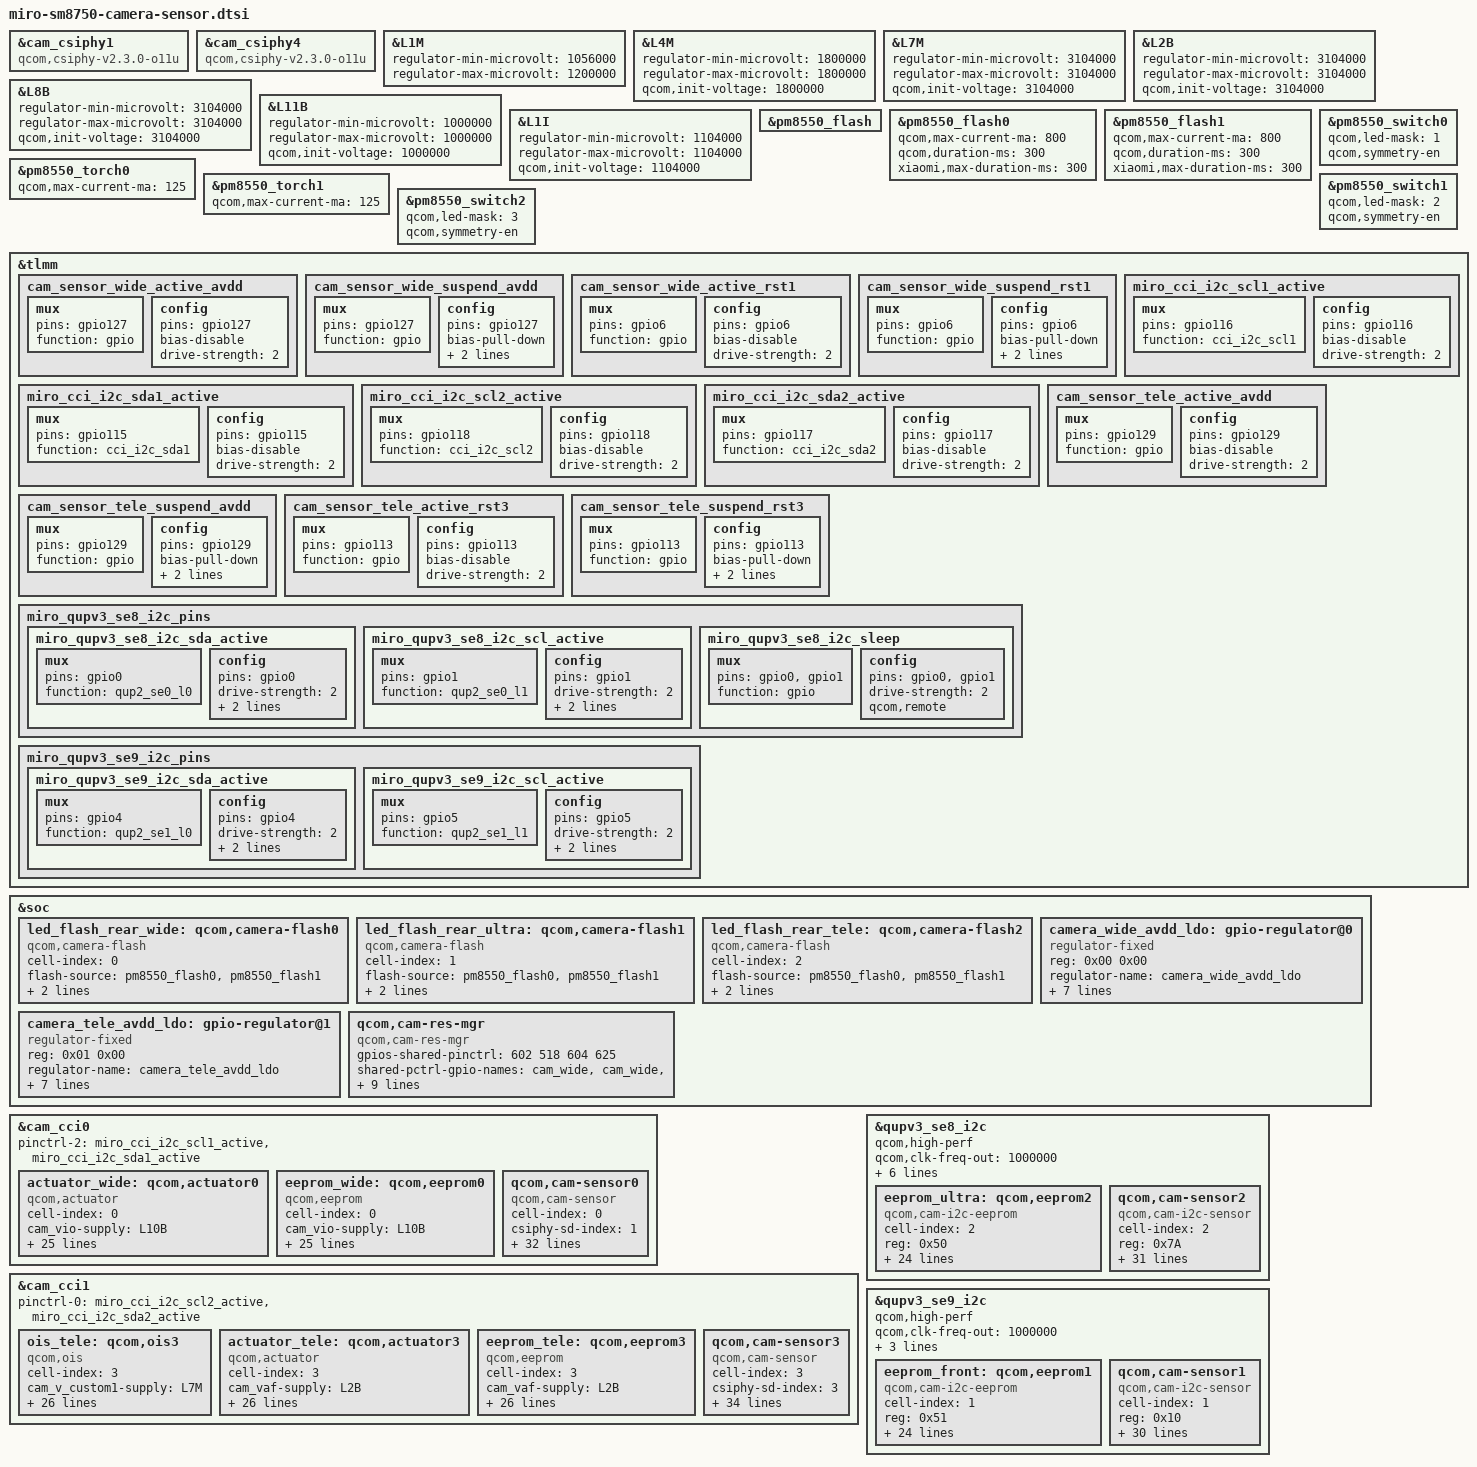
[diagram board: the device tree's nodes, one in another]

#include <dt-bindings/msm-camera.h>

// wide sensor
&cam_csiphy1 {
	compatible = "qcom,csiphy-v2.3.0-o11u", "qcom,csiphy";
};

// front sensor
&cam_csiphy4 {
	compatible = "qcom,csiphy-v2.3.0-o11u", "qcom,csiphy";
};

&L1M {
	regulator-min-microvolt = <1056000>;
	regulator-max-microvolt = <1200000>;
};

&L4M {
	regulator-min-microvolt = <1800000>;
	regulator-max-microvolt = <1800000>;
	qcom,init-voltage = <1800000>;
};

&L7M {
	regulator-min-microvolt = <3104000>;
	regulator-max-microvolt = <3104000>;
	qcom,init-voltage = <3104000>;
};

&L2B {
	regulator-min-microvolt = <3104000>;
	regulator-max-microvolt = <3104000>;
	qcom,init-voltage = <3104000>;
};

&L8B {
	regulator-min-microvolt = <3104000>;
	regulator-max-microvolt = <3104000>;
	qcom,init-voltage = <3104000>;
};

&L11B {
	regulator-min-microvolt = <1000000>;
	regulator-max-microvolt = <1000000>;
	qcom,init-voltage = <1000000>;
};

&L1I {
	regulator-min-microvolt = <1104000>;
	regulator-max-microvolt = <1104000>;
	qcom,init-voltage = <1104000>;
};

&pm8550_flash {
	status = "ok";
};

&pm8550_flash0 {
	qcom,max-current-ma = <800>;
	qcom,duration-ms = <300>;
	xiaomi,max-duration-ms = <300>;
};

&pm8550_flash1 {
	qcom,max-current-ma = <800>;
	qcom,duration-ms = <300>;
	xiaomi,max-duration-ms = <300>;
};

&pm8550_torch0{
	qcom,max-current-ma = <125>;
};

&pm8550_torch1{
	qcom,max-current-ma = <125>;
};

&pm8550_switch0 {
	qcom,led-mask = <1>;
	qcom,symmetry-en;
};

&pm8550_switch1 {
	qcom,led-mask = <2>;
	qcom,symmetry-en;
};

&pm8550_switch2 {
	qcom,led-mask = <3>;
	qcom,symmetry-en;
};

&tlmm {
	//wide avdd
	cam_sensor_wide_active_avdd: cam_sensor_wide_active_avdd {
		mux {
			pins = "gpio127";
			function = "gpio";
		};
		config {
			pins = "gpio127";
			bias-disable; /* No PULL */
			drive-strength = <2>; /* 2 MA */
		};
	};

	cam_sensor_wide_suspend_avdd: cam_sensor_wide_suspend_avdd {
		mux {
			pins = "gpio127";
			function = "gpio";
		};
		config {
			pins = "gpio127";
			bias-pull-down; /* PULL DOWN */
			drive-strength = <2>; /* 2 MA */
			output-low;
		};
	};

	//Wide reset
	cam_sensor_wide_active_rst1: cam_sensor_wide_active_rst1 {
		mux {
			pins = "gpio6";
			function = "gpio";
		};

		config {
			pins = "gpio6";
			bias-disable; /* No PULL */
			drive-strength = <2>; /* 2 MA */
		};
	};

	cam_sensor_wide_suspend_rst1: cam_sensor_wide_suspend_rst1 {
		mux {
			pins = "gpio6";
			function = "gpio";
		};

		config {
			pins = "gpio6";
			bias-pull-down; /* PULL DOWN */
			drive-strength = <2>; /* 2 MA */
			output-low;
		};
	};

	miro_cci_i2c_scl1_active: miro_cci_i2c_scl1_active {
		mux {
			/* CLK, DATA */
			pins = "gpio116";
			function = "cci_i2c_scl1";
		};

		config {
			pins = "gpio116";
			bias-disable; /* NO PULL */
			drive-strength = <2>; /* 2 MA */
		};
	};

	miro_cci_i2c_sda1_active: miro_cci_i2c_sda1_active {
		mux {
			/* CLK, DATA */
			pins = "gpio115";
			function = "cci_i2c_sda1";
		};

		config {
			pins = "gpio115";
			bias-disable; /* NO PULL */
			drive-strength = <2>; /* 2 MA */
		};
	};

	miro_cci_i2c_scl2_active: miro_cci_i2c_scl2_active {
		mux {
			/* CLK, DATA */
			pins = "gpio118";
			function = "cci_i2c_scl2";
		};
		config {
			pins = "gpio118";
			bias-disable; /* NO PULL */
			drive-strength = <2>; /* 2 MA */
		};
	};

	miro_cci_i2c_sda2_active: miro_cci_i2c_sda2_active {
		mux {
			/* CLK, DATA */
			pins = "gpio117";
			function = "cci_i2c_sda2";
		};
		config {
			pins = "gpio117";
			bias-disable; /* NO PULL */
			drive-strength = <2>; /* 2 MA */
		};
	};

	//tele avdd
	cam_sensor_tele_active_avdd: cam_sensor_tele_active_avdd {
		mux {
			pins = "gpio129";
			function = "gpio";
		};
		config {
			pins = "gpio129";
			bias-disable; /* No PULL */
			drive-strength = <2>; /* 2 MA */
		};
	};

	cam_sensor_tele_suspend_avdd: cam_sensor_tele_suspend_avdd {
		mux {
			pins = "gpio129";
			function = "gpio";
		};
		config {
			pins = "gpio129";
			bias-pull-down; /* PULL DOWN */
			drive-strength = <2>; /* 2 MA */
			output-low;
		};
	};

	//Tele reset
	cam_sensor_tele_active_rst3: cam_sensor_tele_active_rst3 {
		mux {
			pins = "gpio113";
			function = "gpio";
		};
		config {
			pins = "gpio113";
			bias-disable; /* No PULL */
			drive-strength = <2>; /* 2 MA */
		};
	};

	cam_sensor_tele_suspend_rst3: cam_sensor_tele_suspend_rst3 {
		mux {
			pins = "gpio113";
			function = "gpio";
		};
		config {
			pins = "gpio113";
			bias-pull-down; /* PULL DOWN */
			drive-strength = <2>; /* 2 MA */
			output-low;
		};
	};

	miro_qupv3_se8_i2c_pins: miro_qupv3_se8_i2c_pins {
		miro_qupv3_se8_i2c_sda_active: miro_qupv3_se8_i2c_sda_active {
			mux {
				pins = "gpio0";
				function = "qup2_se0_l0";
			};

			config {
				pins = "gpio0";
				drive-strength = <2>;
				bias-disable;
				qcom,apps;
			};
		};

		miro_qupv3_se8_i2c_scl_active: miro_qupv3_se8_i2c_scl_active {
			mux {
				pins = "gpio1";
				function = "qup2_se0_l1";
			};

			config {
				pins = "gpio1";
				drive-strength = <2>;
				bias-disable;
				qcom,apps;
			};
		};

		miro_qupv3_se8_i2c_sleep: miro_qupv3_se8_i2c_sleep {
			mux {
				pins = "gpio0", "gpio1";
				function = "gpio";
			};

			config {
				pins = "gpio0", "gpio1";
				drive-strength = <2>;
				qcom,remote;
			};
		};
	};

	miro_qupv3_se9_i2c_pins: miro_qupv3_se9_i2c_pins {
		miro_qupv3_se9_i2c_sda_active: miro_qupv3_se9_i2c_sda_active {
			mux {
				pins = "gpio4";
				function = "qup2_se1_l0";
			};

			config {
				pins = "gpio4";
				drive-strength = <2>;
				bias-disable;
				qcom,apps;
			};
		};

		miro_qupv3_se9_i2c_scl_active: miro_qupv3_se9_i2c_scl_active {
			mux {
				pins = "gpio5";
				function = "qup2_se1_l1";
			};

			config {
				pins = "gpio5";
				drive-strength = <2>;
				bias-disable;
				qcom,apps;
			};
		};
	};
};
&soc {
	led_flash_rear_wide: qcom,camera-flash0 {
		cell-index = <0>;
		compatible = "qcom,camera-flash";
		flash-source = <&pm8550_flash0 &pm8550_flash1>;
		torch-source = <&pm8550_torch0 &pm8550_torch1>;
		switch-source = <&pm8550_switch2>;
		status = "ok";
	};

	led_flash_rear_ultra: qcom,camera-flash1 {
		cell-index = <1>;
		compatible = "qcom,camera-flash";
		flash-source = <&pm8550_flash0 &pm8550_flash1>;
		torch-source = <&pm8550_torch0 &pm8550_torch1>;
		switch-source = <&pm8550_switch2>;
		status = "ok";
	};

	led_flash_rear_tele: qcom,camera-flash2 {
		cell-index = <2>;
		compatible = "qcom,camera-flash";
		flash-source = <&pm8550_flash0 &pm8550_flash1>;
		torch-source = <&pm8550_torch0 &pm8550_torch1>;
		switch-source = <&pm8550_switch2>;
		status = "ok";
	};

	//wide avdd
	camera_wide_avdd_ldo: gpio-regulator@0 {
		compatible = "regulator-fixed";
		reg = <0x00 0x00>;
		regulator-name = "camera_wide_avdd_ldo";
		regulator-min-microvolt = <2800000>;
		regulator-max-microvolt = <2800000>;
		regulator-enable-ramp-delay = <100>;
		enable-active-high;
		gpio = <&tlmm 127 0>;
		pinctrl-names = "wide_avdd_active", "wide_avdd_suspend";
		pinctrl-0 = <&cam_sensor_wide_active_avdd
					 &cam_sensor_wide_suspend_avdd>;
	};

	//tele avdd
	camera_tele_avdd_ldo: gpio-regulator@1 {
		compatible = "regulator-fixed";
		reg = <0x01 0x00>;
		regulator-name = "camera_tele_avdd_ldo";
		regulator-min-microvolt = <2200000>;
		regulator-max-microvolt = <2200000>;
		regulator-enable-ramp-delay = <100>;
		enable-active-high;
		gpio = <&tlmm 129 0>;
		pinctrl-names = "tele_avdd_active", "tele_avdd_suspend";
		pinctrl-0 = <&cam_sensor_tele_active_avdd
		&cam_sensor_tele_suspend_avdd>;
	};

	qcom,cam-res-mgr {
		compatible = "qcom,cam-res-mgr";
		gpios-shared-pinctrl = <602 518 604 625>;
		shared-pctrl-gpio-names = "cam_wide", "cam_wide", "cam_tele", "cam_tele";
		pinctrl-names = "cam_wide_active", "cam_wide_suspend", "cam_tele_active", "cam_tele_suspend";
		pinctrl-0 = <&cam_sensor_mclk1_active
					&cam_sensor_wide_active_rst1>;
		pinctrl-1 = <&cam_sensor_mclk1_suspend
					&cam_sensor_wide_suspend_rst1>;
		pinctrl-2 = <&cam_sensor_mclk3_active
					&cam_sensor_tele_active_rst3>;
		pinctrl-3 = <&cam_sensor_mclk3_suspend
					&cam_sensor_tele_suspend_rst3>;
		status = "ok";
	};
};

&cam_cci0 {
	pinctrl-2 = <&miro_cci_i2c_scl1_active &miro_cci_i2c_sda1_active>;

	// wide actuator
	actuator_wide: qcom,actuator0 {
		cell-index = <0>;
		compatible = "qcom,actuator";
		cam_vio-supply = <&L10B>;
		cam_vdig-supply = <&L1I>;
		cam_clk-supply = <&cam_cc_titan_top_gdsc>;
		cam_vaf-supply = <&L8B>;
		cam_vana-supply = <&camera_wide_avdd_ldo>;
		regulator-names = "cam_vio", "cam_vdig", "cam_clk", "cam_vana", "cam_vaf";
		rgltr-cntrl-support;
		rgltr-min-voltage = <1800000 1104000 0 2800000 3104000>;
		rgltr-max-voltage = <1800000 1104000 0 2800000 3104000>;
		rgltr-load-current = <4000 913000 0 119000 150000>;
		gpio-no-mux = <0>;
		use-shared-clk;
		// pinctrl-names = "cam_default", "cam_suspend";
		// pinctrl-0 = <&cam_sensor_mclk1_active
		// 		 &cam_sensor_wide_active_rst1>;
		// pinctrl-1 = <&cam_sensor_mclk1_suspend
		// 		 &cam_sensor_wide_suspend_rst1>;
		gpios = <&tlmm 90 0>,
			<&tlmm 6 0>;
		gpio-reset = <1>;
		gpio-req-tbl-num = <0 1>;
		gpio-req-tbl-flags = <1 0>;
		gpio-req-tbl-label = "CAMIF_MCLK1",
					"CAM_RESET1";
		cci-master = <CCI_MASTER_1>;
		clocks = <&cambistmclkcc CAM_BIST_MCLK_CC_MCLK1_CLK>;
		clock-names = "cam_clk";
		clock-cntl-level = "nominal";
		clock-rates = <19200000>;
		status = "ok";
	};

	eeprom_wide: qcom,eeprom0 {
		cell-index = <0>;
		compatible = "qcom,eeprom";
		cam_vio-supply = <&L10B>;
		cam_vdig-supply = <&L1I>;
		cam_clk-supply = <&cam_cc_titan_top_gdsc>;
		cam_vaf-supply = <&L8B>;
		cam_vana-supply = <&camera_wide_avdd_ldo>;
		regulator-names = "cam_vio", "cam_vdig", "cam_clk", "cam_vana", "cam_vaf";
		rgltr-cntrl-support;
		rgltr-min-voltage = <1800000 1104000 0 2800000 3104000>;
		rgltr-max-voltage = <1800000 1104000 0 2800000 3104000>;
		rgltr-load-current = <4000 913000 0 119000 150000>;
		gpio-no-mux = <0>;
		use-shared-clk;
		// pinctrl-names = "cam_default", "cam_suspend";
		// pinctrl-0 = <&cam_sensor_mclk1_active
		// 		 &cam_sensor_wide_active_rst1>;
		// pinctrl-1 = <&cam_sensor_mclk1_suspend
		// 		 &cam_sensor_wide_suspend_rst1>;
		gpios = <&tlmm 90 0>,
			<&tlmm 6 0>;
		gpio-reset = <1>;
		gpio-req-tbl-num = <0 1>;
		gpio-req-tbl-flags = <1 0>;
		gpio-req-tbl-label = "CAMIF_MCLK1",
					"CAM_RESET1";
		cci-master = <CCI_MASTER_1>;
		clocks = <&cambistmclkcc CAM_BIST_MCLK_CC_MCLK1_CLK>;
		clock-names = "cam_clk";
		clock-cntl-level = "nominal";
		clock-rates = <19200000>;
		status = "ok";
	};

	qcom,cam-sensor0 {
		cell-index = <0>;
		compatible = "qcom,cam-sensor";
		csiphy-sd-index = <1>;
		eeprom-src = <&eeprom_wide>;
		actuator-src = <&actuator_wide>;
		led-flash-src = <&led_flash_rear_wide>;
		sensor-position-roll = <90>;
		sensor-position-pitch = <0>;
		sensor-position-yaw = <180>;
		cam_vio-supply = <&L10B>;
		cam_vdig-supply = <&L1I>;
		cam_clk-supply = <&cam_cc_titan_top_gdsc>;
		cam_vaf-supply = <&L8B>;
		cam_vana-supply = <&camera_wide_avdd_ldo>;
		regulator-names = "cam_vio", "cam_vdig", "cam_clk", "cam_vana", "cam_vaf";
		rgltr-cntrl-support;
		rgltr-min-voltage = <1800000 1104000 0 2800000 3104000>;
		rgltr-max-voltage = <1800000 1104000 0 2800000 3104000>;
		rgltr-load-current = <4000 913000 0 119000 150000>;
		gpio-no-mux = <0>;
		use-shared-clk;
		// pinctrl-names = "cam_default", "cam_suspend";
		// pinctrl-0 = <&cam_sensor_mclk1_active
		// 		 &cam_sensor_wide_active_rst1>;
		// pinctrl-1 = <&cam_sensor_mclk1_suspend
		// 		 &cam_sensor_wide_suspend_rst1>;
		gpios = <&tlmm 90 0>,
			<&tlmm 6 0>;
		gpio-reset = <1>;
		gpio-req-tbl-num = <0 1>;
		gpio-req-tbl-flags = <1 0>;
		gpio-req-tbl-label = "CAMIF_MCLK1",
					"CAM_RESET1";
		cci-master = <CCI_MASTER_1>;
		clocks = <&cambistmclkcc CAM_BIST_MCLK_CC_MCLK1_CLK>;
		clock-names = "cam_clk";
		clock-cntl-level = "nominal";
		clock-rates = <19200000>;
		status = "ok";
	};
};

&cam_cci1 {
	pinctrl-0 = <&miro_cci_i2c_scl2_active &miro_cci_i2c_sda2_active>;

	// tele ois
	ois_tele: qcom,ois3 {
		cell-index = <3>;
		compatible = "qcom,ois";
		cam_v_custom1-supply = <&L7M>;
		cam_vaf-supply = <&L2B>;
		cam_vio-supply = <&L10B>;
		cam_vdig-supply = <&L11B>;
		cam_clk-supply = <&cam_cc_titan_top_gdsc>;
		cam_vana-supply = <&camera_tele_avdd_ldo>;
		regulator-names = "cam_vio", "cam_vdig", "cam_clk", "cam_vana", "cam_vaf", "cam_v_custom1";
		rgltr-cntrl-support;
		rgltr-min-voltage = <1800000 1000000 0 2200000 3104000 3104000>;
		rgltr-max-voltage = <1800000 1000000 0 2200000 3104000 3104000>;
		rgltr-load-current = <50000 590000 0 85000 150000 150000>;
		gpio-no-mux = <0>;
		use-shared-clk;
		// pinctrl-names = "cam_default", "cam_suspend";
		// pinctrl-0 = <&cam_sensor_mclk3_active
		// 			&cam_sensor_tele_active_rst3>;
		// pinctrl-1 = <&cam_sensor_mclk3_suspend
		// 			&cam_sensor_tele_suspend_rst3>;
		gpios = <&tlmm 92 0>,
				<&tlmm 113 0>;
		gpio-reset = <1>;
		gpio-req-tbl-num = <0 1>;
		gpio-req-tbl-flags = <1 0>;
		gpio-req-tbl-label = "CAMIF_MCLK3",
							 "CAM_RESET3";
		cci-master = <CCI_MASTER_0>;
		clocks = <&cambistmclkcc CAM_BIST_MCLK_CC_MCLK3_CLK>;
		clock-names = "cam_clk";
		clock-cntl-level = "nominal";
		clock-rates = <19200000>;
		status = "ok";
	};

	// tele actuator
	actuator_tele: qcom,actuator3 {
		cell-index = <3>;
		compatible = "qcom,actuator";
		cam_vaf-supply = <&L2B>;
		cam_vio-supply = <&L10B>;
		cam_vdig-supply = <&L11B>;
		cam_v_custom1-supply = <&L7M>;
		cam_clk-supply = <&cam_cc_titan_top_gdsc>;
		cam_vana-supply = <&camera_tele_avdd_ldo>;
		regulator-names = "cam_vio", "cam_vdig", "cam_clk", "cam_vana", "cam_vaf", "cam_v_custom1";
		rgltr-cntrl-support;
		rgltr-min-voltage = <1800000 1000000 0 2200000 3104000 3104000>;
		rgltr-max-voltage = <1800000 1000000 0 2200000 3104000 3104000>;
		rgltr-load-current = <50000 590000 0 85000 150000 150000>;
		gpio-no-mux = <0>;
		use-shared-clk;
		// pinctrl-names = "cam_default", "cam_suspend";
		// pinctrl-0 = <&cam_sensor_mclk3_active
		// 			&cam_sensor_tele_active_rst3>;
		// pinctrl-1 = <&cam_sensor_mclk3_suspend
		// 			&cam_sensor_tele_suspend_rst3>;
		gpios = <&tlmm 92 0>,
				<&tlmm 113 0>;
		gpio-reset = <1>;
		gpio-req-tbl-num = <0 1>;
		gpio-req-tbl-flags = <1 0>;
		gpio-req-tbl-label = "CAMIF_MCLK3",
							 "CAM_RESET3";
		cci-master = <CCI_MASTER_0>;
		clocks = <&cambistmclkcc CAM_BIST_MCLK_CC_MCLK3_CLK>;
		clock-names = "cam_clk";
		clock-cntl-level = "nominal";
		clock-rates = <19200000>;
		status = "ok";
	};

	eeprom_tele: qcom,eeprom3 {
		cell-index = <3>;
		compatible = "qcom,eeprom";
		cam_vaf-supply = <&L2B>;
		cam_vio-supply = <&L10B>;
		cam_vdig-supply = <&L11B>;
		cam_v_custom1-supply = <&L7M>;
		cam_clk-supply = <&cam_cc_titan_top_gdsc>;
		cam_vana-supply = <&camera_tele_avdd_ldo>;
		regulator-names = "cam_vio", "cam_vdig", "cam_clk", "cam_vana", "cam_vaf", "cam_v_custom1";
		rgltr-cntrl-support;
		rgltr-min-voltage = <1800000 1000000 0 2200000 3104000 3104000>;
		rgltr-max-voltage = <1800000 1000000 0 2200000 3104000 3104000>;
		rgltr-load-current = <50000 590000 0 85000 150000 150000>;
		gpio-no-mux = <0>;
		use-shared-clk;
		// pinctrl-names = "cam_default", "cam_suspend";
		// pinctrl-0 = <&cam_sensor_mclk3_active
		// 			&cam_sensor_tele_active_rst3>;
		// pinctrl-1 = <&cam_sensor_mclk3_suspend
		// 			&cam_sensor_tele_suspend_rst3>;
		gpios = <&tlmm 92 0>,
				<&tlmm 113 0>;
		gpio-reset = <1>;
		gpio-req-tbl-num = <0 1>;
		gpio-req-tbl-flags = <1 0>;
		gpio-req-tbl-label = "CAMIF_MCLK3",
							 "CAM_RESET3";
		cci-master = <CCI_MASTER_0>;
		clocks = <&cambistmclkcc CAM_BIST_MCLK_CC_MCLK3_CLK>;
		clock-names = "cam_clk";
		clock-cntl-level = "nominal";
		clock-rates = <19200000>;
		status = "ok";
	};

	// tele Sensor
	qcom,cam-sensor3 {
		cell-index = <3>;
		compatible = "qcom,cam-sensor";
		csiphy-sd-index = <3>;
		led-flash-src = <&led_flash_rear_tele>;
		eeprom-src = <&eeprom_tele>;
		actuator-src = <&actuator_tele>;
		ois-src = <&ois_tele>;
		sensor-position-roll = <90>;
		sensor-position-pitch = <0>;
		sensor-position-yaw = <180>;
		cam_vaf-supply = <&L2B>;
		cam_vio-supply = <&L10B>;
		cam_vdig-supply = <&L11B>;
		cam_v_custom1-supply = <&L7M>;
		cam_clk-supply = <&cam_cc_titan_top_gdsc>;
		cam_vana-supply = <&camera_tele_avdd_ldo>;
		regulator-names = "cam_vio", "cam_vdig", "cam_clk", "cam_vana", "cam_vaf", "cam_v_custom1";
		rgltr-cntrl-support;
		rgltr-min-voltage = <1800000 1000000 0 2200000 3104000 3104000>;
		rgltr-max-voltage = <1800000 1000000 0 2200000 3104000 3104000>;
		rgltr-load-current = <50000 590000 0 85000 150000 150000>;
		gpio-no-mux = <0>;
		use-shared-clk;
		// pinctrl-names = "cam_default", "cam_suspend";
		// pinctrl-0 = <&cam_sensor_mclk3_active
		// 			&cam_sensor_tele_active_rst3>;
		// pinctrl-1 = <&cam_sensor_mclk3_suspend
		// 			&cam_sensor_tele_suspend_rst3>;
		gpios = <&tlmm 92 0>,
				<&tlmm 113 0>;
		gpio-reset = <1>;
		gpio-req-tbl-num = <0 1>;
		gpio-req-tbl-flags = <1 0>;
		gpio-req-tbl-label = "CAMIF_MCLK3",
							 "CAM_RESET3";
		cci-master = <CCI_MASTER_0>;
		clocks = <&cambistmclkcc CAM_BIST_MCLK_CC_MCLK3_CLK>;
		clock-names = "cam_clk";
		clock-cntl-level = "nominal";
		clock-rates = <19200000>;
		status = "ok";
	};
};

&qupv3_se8_i2c {
	status = "ok";
	qcom,high-perf;
	qcom,clk-freq-out = <1000000>;
	qcom,pm-ctrl-client;
	pinctrl-0 = <&miro_qupv3_se8_i2c_sda_active>, <&miro_qupv3_se8_i2c_scl_active>;
	pinctrl-1 = <&miro_qupv3_se8_i2c_sleep>;
	dmas = <&gpi_dma2 0 0 3 1024 0>,
		<&gpi_dma2 1 0 3 1024 0>;

	eeprom_ultra: qcom,eeprom2 {
		cell-index = <2>;
		reg = <0x50>;
		compatible = "qcom,cam-i2c-eeprom";
		cam_vio-supply = <&L4M>;
		cam_vdig-supply = <&L2M>;
		cam_clk-supply = <&cam_cc_titan_top_gdsc>;
		cam_vana-supply = <&L6M>;
		regulator-names = "cam_vio", "cam_vdig","cam_clk", "cam_vana";
		rgltr-cntrl-support;
		rgltr-min-voltage = <1800000 1056000 0 2800000>;
		rgltr-max-voltage = <1800000 1056000 0 2800000>;
		rgltr-load-current = <150000 150000 0  150000>;
		gpio-no-mux = <0>;
		pinctrl-names = "cam_default", "cam_suspend";
		pinctrl-0 = <&cam_sensor_mclk2_active
					&cam_sensor_active_rst2>;
		pinctrl-1 = <&cam_sensor_mclk2_suspend
					&cam_sensor_suspend_rst2>;
		gpios = <&tlmm 91 0>, <&tlmm 3 0>;
		gpio-reset = <1>;
		gpio-req-tbl-num = <0 1>;
		gpio-req-tbl-flags = <1 0>;
		gpio-req-tbl-label = "CAMUW_MCLK2", "CAMUW_RESET2";
		clocks = <&cambistmclkcc CAM_BIST_MCLK_CC_MCLK2_CLK>;
		clock-names = "cam_clk";
		clock-cntl-level = "nominal";
		clock-rates = <19200000>;
		status = "ok";
	};

	// uw sensor
	qcom,cam-sensor2 {
		cell-index = <2>;
		reg = <0x7A>;
		compatible = "qcom,cam-i2c-sensor";
		csiphy-sd-index = <2>;
		led-flash-src = <&led_flash_rear_ultra>;
		eeprom-src = <&eeprom_ultra>;
		sensor-position-roll = <90>;
		sensor-position-pitch = <0>;
		sensor-position-yaw = <180>;
		cam_vio-supply = <&L4M>;
		cam_vdig-supply = <&L2M>;
		cam_clk-supply = <&cam_cc_titan_top_gdsc>;
		cam_vana-supply = <&L6M>;
		regulator-names = "cam_vio", "cam_vdig","cam_clk", "cam_vana";
		rgltr-cntrl-support;
		aon-camera-id = <AON_CAM2>;
		rgltr-min-voltage = <1800000 1056000 0 2800000>;
		rgltr-max-voltage = <1800000 1056000 0 2800000>;
		rgltr-load-current = <150000 150000 0  150000>;
		gpio-no-mux = <0>;
		pinctrl-names = "cam_default", "cam_suspend";
		pinctrl-0 = <&cam_sensor_mclk2_active
					&cam_sensor_active_rst2>;
		pinctrl-1 = <&cam_sensor_mclk2_suspend
					&cam_sensor_suspend_rst2>;
		gpios = <&tlmm 91 0>, <&tlmm 3 0>;
		gpio-reset = <1>;
		gpio-req-tbl-num = <0 1>;
		gpio-req-tbl-flags = <1 0>;
		gpio-req-tbl-label = "CAMUW_MCLK2", "CAMUW_RESET2";
		clocks = <&cambistmclkcc CAM_BIST_MCLK_CC_MCLK2_CLK>;
		clock-names = "cam_clk";
		clock-cntl-level = "nominal";
		clock-rates = <19200000>;
		status = "ok";
	};
};

&qupv3_se9_i2c {
	status = "ok";
	qcom,high-perf;
	qcom,clk-freq-out = <1000000>;
	qcom,pm-ctrl-client;
	pinctrl-0 = <&miro_qupv3_se9_i2c_scl_active>, <&miro_qupv3_se9_i2c_sda_active>;

	eeprom_front: qcom,eeprom1 {
		cell-index = <1>;
		reg = <0x51>;
		compatible = "qcom,cam-i2c-eeprom";
		cam_vana-supply = <&L3M>;
		cam_vio-supply = <&L5M>;
		cam_vdig-supply = <&L1M>;
		cam_clk-supply = <&cam_cc_titan_top_gdsc>;
		regulator-names = "cam_vana", "cam_vio",
			"cam_vdig", "cam_clk";
		rgltr-cntrl-support;
		rgltr-min-voltage = <2800000 1800000 1056000 0>;
		rgltr-max-voltage = <2800000 1800000 1200000 0>;
		rgltr-load-current = <150000 150000 913000 0>;
		gpio-no-mux = <0>;
		pinctrl-names = "cam_default", "cam_suspend";
		pinctrl-0 = <&cam_sensor_mclk4_active
			&cam_sensor_active_rst4>;
		pinctrl-1 = <&cam_sensor_mclk4_suspend
			&cam_sensor_suspend_rst4>;
		gpios = <&tlmm 93 0>, <&tlmm 7 0>;
		gpio-reset = <1>;
		gpio-req-tbl-num = <0 1>;
		gpio-req-tbl-flags = <1 0>;
		gpio-req-tbl-label = "CAMIF_MCLK4", "CAM_RESET4";
		clocks = <&cambistmclkcc CAM_BIST_MCLK_CC_MCLK4_CLK>;
		clock-names = "cam_clk";
		clock-cntl-level = "nominal";
		clock-rates = <19200000>;
		status = "ok";
	};

	// Front Sensor
	qcom,cam-sensor1 {
		cell-index = <1>;
		reg = <0x10>;
		compatible = "qcom,cam-i2c-sensor";
		csiphy-sd-index = <4>;
		eeprom-src = <&eeprom_front>;
		sensor-position-roll = <270>;
		sensor-position-pitch = <0>;
		sensor-position-yaw = <0>;
		cam_vana-supply = <&L3M>;
		cam_vio-supply = <&L5M>;
		cam_vdig-supply = <&L1M>;
		cam_clk-supply = <&cam_cc_titan_top_gdsc>;
		regulator-names = "cam_vana", "cam_vio",
			"cam_vdig", "cam_clk";
		rgltr-cntrl-support;
		aon-camera-id = <AON_CAM1>;
		rgltr-min-voltage = <2800000 1800000 1056000 0>;
		rgltr-max-voltage = <2800000 1800000 1200000 0>;
		rgltr-load-current = <150000 150000 913000 0>;
		gpio-no-mux = <0>;
		pinctrl-names = "cam_default", "cam_suspend";
		pinctrl-0 = <&cam_sensor_mclk4_active
			&cam_sensor_active_rst4>;
		pinctrl-1 = <&cam_sensor_mclk4_suspend
			&cam_sensor_suspend_rst4>;
		gpios = <&tlmm 93 0>, <&tlmm 7 0>;
		gpio-reset = <1>;
		gpio-req-tbl-num = <0 1>;
		gpio-req-tbl-flags = <1 0>;
		gpio-req-tbl-label = "CAMIF_MCLK4", "CAM_RESET4";
		clocks = <&cambistmclkcc CAM_BIST_MCLK_CC_MCLK4_CLK>;
		clock-names = "cam_clk";
		clock-cntl-level = "nominal";
		clock-rates = <19200000>;
		status = "ok";
	};
};
